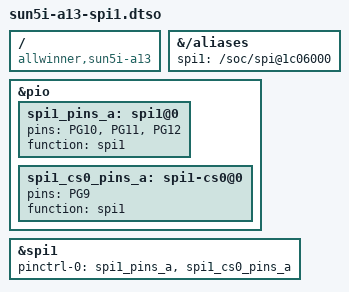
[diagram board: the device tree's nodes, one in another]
/dts-v1/;
/plugin/;

/ {
	compatible = "allwinner,sun5i-a13";

	fragment@0 {
		target-path = "/aliases";
		__overlay__ {
			spi1 = "/soc/spi@1c06000";
		};
	};

	fragment@1 {
		target = <&pio>;
		__overlay__ {
			spi1_pins_a: spi1@0 {
				pins = "PG10", "PG11", "PG12";
				function = "spi1";
			};

			spi1_cs0_pins_a: spi1-cs0@0 {
				pins = "PG9";
				function = "spi1";
			};
		};
	};

	fragment@2 {
		target = <&spi1>;
		__overlay__ {
			status = "okay";
			pinctrl-names = "default";
			pinctrl-0 = <&spi1_pins_a>, <&spi1_cs0_pins_a>;
		};
	};


};
